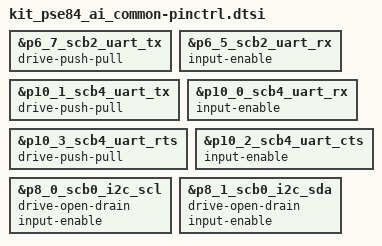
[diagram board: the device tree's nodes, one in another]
/*
 * Copyright (c) 2025 Infineon Technologies AG,
 * or an affiliate of Infineon Technologies AG.
 *
 * SPDX-License-Identifier: Apache-2.0
 */

/* Configure pin control bias mode for uart2 pins */
&p6_7_scb2_uart_tx {
	drive-push-pull;
};

&p6_5_scb2_uart_rx {
	input-enable;
};

&p10_1_scb4_uart_tx {
	drive-push-pull;
};

&p10_0_scb4_uart_rx {
	input-enable;
};

&p10_3_scb4_uart_rts {
	drive-push-pull;
};

&p10_2_scb4_uart_cts {
	input-enable;
};

/* Configure pin control bias mode for i2c0 pins */
&p8_0_scb0_i2c_scl {
	drive-open-drain;
	input-enable;
};

&p8_1_scb0_i2c_sda {
	drive-open-drain;
	input-enable;
};
